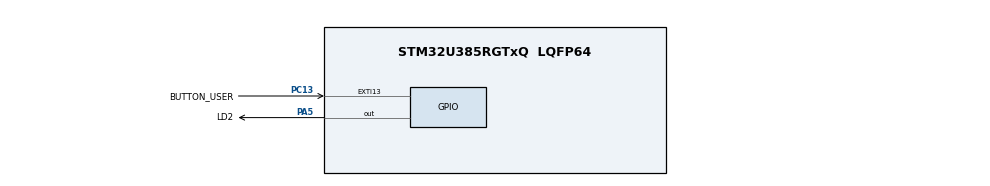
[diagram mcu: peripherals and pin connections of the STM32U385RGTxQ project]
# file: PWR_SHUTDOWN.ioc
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CORTEX_M33_NS.userName=CORTEX_M33
Mcu.Family=STM32U3
Mcu.Name=STM32U385RGTxQ
Mcu.Package=LQFP64
NVIC.EXTI13_IRQn=true\:0\:0\:false\:false\:true\:true\:true\:true
NVIC.PriorityGroup=NVIC_PRIORITYGROUP_4
PA5.GPIO_Label=LD2
PA5.Signal=GPIO_Output
PC13.GPIO_Label=BUTTON_USER
PC13.GPIO_PuPd=GPIO_PULLDOWN
PC13.Signal=GPXTI13
ProjectManager.HeapSize=0x200
ProjectManager.StackSize=0x400
ProjectManager.TargetToolchain=EWARM V9.20
RCC.ADCFreq_Value=96000000
RCC.AHBFreq_Value=96000000
RCC.APB1Freq_Value=96000000
RCC.APB1TimFreq_Value=96000000
RCC.APB2Freq_Value=96000000
RCC.APB2TimFreq_Value=96000000
RCC.APB3Freq_Value=96000000
RCC.CortexFreq_Value=12000000
RCC.HCLKFreq_Value=96000000
RCC.HSE_VALUE=16000000
RCC.HSI48_VALUE=48000000
RCC.HSI_VALUE=16000000
RCC.LSE_VALUE=32768
RCC.LSIDIV_VALUE=32000
RCC.MSISDIV=RCC_MSI_DIV1
RCC.MSI_VALUE=96000000
RCC.PWR_Regulator_Voltage_Scale=PWR_REGULATOR_VOLTAGE_SCALE1
RCC.SYSCLKFreq_VALUE=96000000
RCC.USBFreq_Value=96000000
VP_ICACHE_VS_ICACHE.Mode=DirectMappedCache
VP_PWR_VS_DBSignals.Mode=DisableDeadBatterySignals
VP_PWR_VS_LPOM.Mode=PowerOptimisation
VP_PWR_VS_SECSignals.Mode=Security/Privilege
board=custom

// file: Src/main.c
/* USER CODE BEGIN Header */
/**
  ******************************************************************************
  * @file           : main.c
  * @brief          : Main program body
  ******************************************************************************
  * @attention
  *
  * Copyright (c) 2024 STMicroelectronics.
  * All rights reserved.
  *
  * This software is licensed under terms that can be found in the LICENSE file
  * in the root directory of this software component.
  * If no LICENSE file comes with this software, it is provided AS-IS.
  *
  ******************************************************************************
  */
/* USER CODE END Header */
#include "main.h"

/* USER CODE BEGIN Includes */
#include "stm32u3xx_nucleo.h"
/* USER CODE END Includes */

/* USER CODE BEGIN PV */
/* Private variables ---------------------------------------------------------*/
/* Delay set between each LED turn-on/off while LED is toggling */
#define LED_TOGGLE_DELAY         100
/* Delay set to keep LED turned on when out-of-shutdown detected */
#define LED_FREEZE_DELAY         50

static __IO uint32_t TimingDelay;
static __IO uint32_t counter;             /* ad-hoc counter set to keep LED
                                             on for about 4 sec. when out-of-
                                             shutdown exit detected */
static __IO uint32_t out_of_shutdown;     /* flag initialized at 0, set when
                                             exit from shutdown detected */

/* USER CODE END PV */

void SystemClock_Config(void);
static void MX_GPIO_Init(void);
static void MX_ICACHE_Init(void);
/* USER CODE BEGIN PFP */
/* Private function prototypes -----------------------------------------------*/

/* USER CODE END PFP */

int main(void)
{

  /* USER CODE BEGIN 1 */
  out_of_shutdown = 0;
  counter = LED_FREEZE_DELAY;

  /* USER CODE END 1 */

  /* MCU Configuration--------------------------------------------------------*/

  /* Reset of all peripherals, Initializes the Flash interface and the Systick. */
  HAL_Init();

  /* Configure the system clock */
  SystemClock_Config();

  /* USER CODE BEGIN SysInit */
  /* Configure the system Power Supply */
  if(HAL_PWREx_ConfigSupply(PWR_SMPS_SUPPLY) != HAL_OK)
  {
    Error_Handler();
  }
  /* USER CODE END SysInit */

  /* Initialize all configured peripherals */
  MX_GPIO_Init();
  MX_ICACHE_Init();
  /* USER CODE BEGIN 2 */

  /* Enable access to Backup domain */
  HAL_PWR_EnableBkUpAccess();

  /* Check if the system was resumed from shutdown mode,
     resort to RTC back-up register RTC_BKP31R to verify
     whether or not shutdown entry flag was set by software
     before entering shutdown mode.  */
  if (READ_REG(TAMP->BKP31R) == 1)
  {
    WRITE_REG(TAMP->BKP31R, 0x0 );  /* reset back-up register */
    out_of_shutdown = 1;            /* out of shutdown detected */
    /* Wait that user release the User push-button */
    BSP_PB_Init(BUTTON_USER, BUTTON_MODE_GPIO);
    while(BSP_PB_GetState(BUTTON_USER) == GPIO_PIN_RESET){}
  }

  /* Check and Clear the Wakeup flag */
  if (__HAL_PWR_GET_FLAG(PWR_WAKEUP_FLAG2) != RESET)
  {
    __HAL_PWR_CLEAR_FLAG(PWR_WAKEUP_FLAG2);
  }

  /* Initialize the User push-button to generate external interrupts */
  BSP_PB_Init(BUTTON_USER, BUTTON_MODE_EXTI);

  /* Turn on LD2 */
  BSP_LED_On(LD2);
  /* USER CODE END 2 */

  /* Infinite loop */
  while (1)
  {

  }
}

void SystemClock_Config(void)
{
  RCC_OscInitTypeDef RCC_OscInitStruct = {0};
  RCC_ClkInitTypeDef RCC_ClkInitStruct = {0};

  /** Enable Epod Booster
  */
  if (HAL_RCCEx_EpodBoosterClkConfig(RCC_EPODBOOSTER_SOURCE_MSIS, RCC_EPODBOOSTER_DIV1) != HAL_OK)
  {
    Error_Handler();
  }

  if (HAL_PWREx_EnableEpodBooster() != HAL_OK)
  {
    Error_Handler();
  }

  /** Configure the main internal regulator output voltage
  */
  if (HAL_PWREx_ControlVoltageScaling(PWR_REGULATOR_VOLTAGE_SCALE1) != HAL_OK)
  {
    Error_Handler();
  }

  /** Set Flash latency before increasing MSIS
  */
  __HAL_FLASH_SET_LATENCY(FLASH_LATENCY_2);

  /** Initializes the CPU, AHB and APB buses clocks
  */
  RCC_OscInitStruct.OscillatorType = RCC_OSCILLATORTYPE_MSIS;
  RCC_OscInitStruct.MSISState = RCC_MSI_ON;
  RCC_OscInitStruct.MSISSource = RCC_MSI_RC0;
  RCC_OscInitStruct.MSISDiv = RCC_MSI_DIV1;
  if (HAL_RCC_OscConfig(&RCC_OscInitStruct) != HAL_OK)
  {
    Error_Handler();
  }

  /** Initializes the CPU, AHB and APB buses clocks
  */
  RCC_ClkInitStruct.ClockType = RCC_CLOCKTYPE_HCLK|RCC_CLOCKTYPE_SYSCLK
                              |RCC_CLOCKTYPE_PCLK1|RCC_CLOCKTYPE_PCLK2
                              |RCC_CLOCKTYPE_PCLK3;
  RCC_ClkInitStruct.SYSCLKSource = RCC_SYSCLKSOURCE_MSIS;
  RCC_ClkInitStruct.AHBCLKDivider = RCC_SYSCLK_DIV1;
  RCC_ClkInitStruct.APB1CLKDivider = RCC_HCLK_DIV1;
  RCC_ClkInitStruct.APB2CLKDivider = RCC_HCLK_DIV1;
  RCC_ClkInitStruct.APB3CLKDivider = RCC_HCLK_DIV1;

  if (HAL_RCC_ClockConfig(&RCC_ClkInitStruct, FLASH_LATENCY_2) != HAL_OK)
  {
    Error_Handler();
  }
}

static void MX_ICACHE_Init(void)
{

  /** Enable instruction cache in 1-way (direct mapped cache)
  */
  if (HAL_ICACHE_ConfigAssociativityMode(ICACHE_1WAY) != HAL_OK)
  {
    Error_Handler();
  }
  if (HAL_ICACHE_Enable() != HAL_OK)
  {
    Error_Handler();
  }

}

static void MX_GPIO_Init(void)
{
  GPIO_InitTypeDef GPIO_InitStruct = {0};

  /* GPIO Ports Clock Enable */
  __HAL_RCC_GPIOC_CLK_ENABLE();
  __HAL_RCC_GPIOA_CLK_ENABLE();

  /*Configure GPIO pin Output Level */
  HAL_GPIO_WritePin(LD2_GPIO_Port, LD2_Pin, GPIO_PIN_RESET);

  /*Configure GPIO pin : BUTTON_USER_Pin */
  GPIO_InitStruct.Pin = BUTTON_USER_Pin;
  GPIO_InitStruct.Mode = GPIO_MODE_IT_RISING;
  GPIO_InitStruct.Pull = GPIO_PULLDOWN;
  HAL_GPIO_Init(BUTTON_USER_GPIO_Port, &GPIO_InitStruct);

  /*Configure GPIO pin : LD2_Pin */
  GPIO_InitStruct.Pin = LD2_Pin;
  GPIO_InitStruct.Mode = GPIO_MODE_OUTPUT_PP;
  GPIO_InitStruct.Pull = GPIO_NOPULL;
  GPIO_InitStruct.Speed = GPIO_SPEED_FREQ_LOW;
  HAL_GPIO_Init(LD2_GPIO_Port, &GPIO_InitStruct);

  /* EXTI interrupt init*/
  HAL_NVIC_SetPriority(EXTI13_IRQn, 0, 0);
  HAL_NVIC_EnableIRQ(EXTI13_IRQn);

}

/* USER CODE BEGIN 4 */

/**
  * @brief SYSTICK callback
  * @param None
  * @retval None
  */
void HAL_SYSTICK_Callback(void)
{
  if (TimingDelay != 0)
  {
    TimingDelay--;
  }
  else
  {
    /* Keep LD2 on for about 5 sec. when out-of-shutdown detected */
    if ((out_of_shutdown == 1) && (counter > 0))
    {
      BSP_LED_On(LD2);

      counter--;
    }
    else
    {
      /* Toggle LD2 */
      BSP_LED_Toggle(LD2);
    }
    TimingDelay = LED_TOGGLE_DELAY;
  }
}

/**
  * @brief EXTI line detection callbacks
  * @param GPIO_Pin: Specifies the pins connected EXTI line
  * @retval None
  */
void HAL_GPIO_EXTI_Rising_Callback(uint16_t GPIO_Pin)
{
  if (GPIO_Pin == BUTTON_USER_PIN)
  {
    /* Wait that user release the User push-button */
    while(BSP_PB_GetState(BUTTON_USER) == GPIO_PIN_RESET){}

    /* Disable all used wakeup sources: WKUP line */
    HAL_PWR_DisableWakeUpLine(PWR_WAKEUP_LINE2);

    /* Clear wake up Flag */
    __HAL_PWR_CLEAR_FLAG(PWR_WAKEUP_FLAG2);

    /* Enable wakeup line WKUP2 */
    HAL_PWR_EnableWakeUpLine(PWR_WAKEUP_LINE2, PWR_WAKEUP_SELECT_1, PWR_WAKEUP_POLARITY_HIGH);
    /* Set RTC back-up register RTC_BKP31R to indicate
       later on that system has entered shutdown mode  */
    WRITE_REG(TAMP->BKP31R, 0x1);

    /* Deinit LD2 pin */
    BSP_LED_DeInit(LD2);

    /* Enter shutdown mode */
    HAL_PWREx_EnterSHUTDOWNMode();
  }
}
/* USER CODE END 4 */

void Error_Handler(void)
{
  __disable_irq();
  while (1)
  {
  }
}
